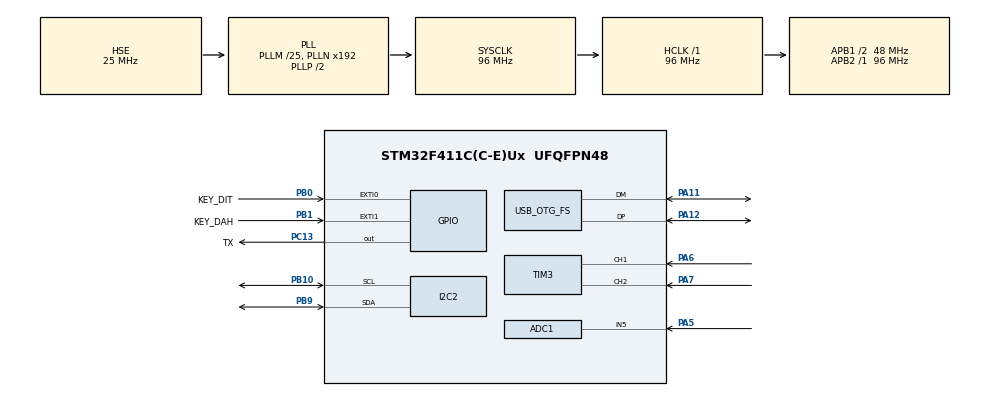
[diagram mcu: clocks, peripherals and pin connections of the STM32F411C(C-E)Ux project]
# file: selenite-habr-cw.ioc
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ADC1.Channel-0\#ChannelRegularConversion=ADC_CHANNEL_5
ADC1.NbrOfConversionFlag=1
ADC1.Rank-0\#ChannelRegularConversion=1
ADC1.SamplingTime-0\#ChannelRegularConversion=ADC_SAMPLETIME_3CYCLES
ADC1.master=1
Mcu.Family=STM32F4
Mcu.Name=STM32F411C(C-E)Ux
Mcu.Package=UFQFPN48
NVIC.ADC_IRQn=true\:0\:0\:false\:false\:true\:true\:true\:true
NVIC.EXTI0_IRQn=true\:0\:0\:false\:false\:true\:true\:true\:true
NVIC.EXTI1_IRQn=true\:0\:0\:false\:false\:true\:true\:true\:true
NVIC.OTG_FS_IRQn=true\:0\:0\:false\:false\:true\:false\:true\:true
NVIC.PriorityGroup=NVIC_PRIORITYGROUP_4
PA11.Mode=Device_Only
PA11.Signal=USB_OTG_FS_DM
PA12.Mode=Device_Only
PA12.Signal=USB_OTG_FS_DP
PA13.Mode=Serial_Wire
PA13.Signal=SYS_JTMS-SWDIO
PA14.Mode=Serial_Wire
PA14.Signal=SYS_JTCK-SWCLK
PA5.Signal=ADCx_IN5
PA6.GPIO_PuPd=GPIO_PULLUP
PA6.Signal=S_TIM3_CH1
PA7.GPIO_PuPd=GPIO_PULLUP
PA7.Signal=S_TIM3_CH2
PB0.GPIO_Label=KEY_DIT
PB0.GPIO_ModeDefaultEXTI=GPIO_MODE_IT_RISING_FALLING
PB0.GPIO_PuPd=GPIO_PULLUP
PB0.Signal=GPXTI0
PB1.GPIO_Label=KEY_DAH
PB1.GPIO_ModeDefaultEXTI=GPIO_MODE_IT_RISING_FALLING
PB1.GPIO_PuPd=GPIO_PULLUP
PB1.Signal=GPXTI1
PB10.Mode=I2C
PB10.Signal=I2C2_SCL
PB9.Mode=I2C
PB9.Signal=I2C2_SDA
PC13-ANTI_TAMP.GPIO_Label=TX
PC13-ANTI_TAMP.PinState=GPIO_PIN_SET
PC13-ANTI_TAMP.Signal=GPIO_Output
PH0\ -\ OSC_IN.Mode=HSE-External-Oscillator
PH0\ -\ OSC_IN.Signal=RCC_OSC_IN
PH1\ -\ OSC_OUT.Mode=HSE-External-Oscillator
PH1\ -\ OSC_OUT.Signal=RCC_OSC_OUT
ProjectManager.HeapSize=0x200
ProjectManager.StackSize=0x400
ProjectManager.TargetToolchain=STM32CubeIDE
RCC.48MHZClocksFreq_Value=48000000
RCC.AHBFreq_Value=96000000
RCC.APB1CLKDivider=RCC_HCLK_DIV2
RCC.APB1Freq_Value=48000000
RCC.APB1TimFreq_Value=96000000
RCC.APB2Freq_Value=96000000
RCC.APB2TimFreq_Value=96000000
RCC.CortexFreq_Value=96000000
RCC.EXTERNAL_CLOCK_VALUE=98304000
RCC.HCLKFreq_Value=96000000
RCC.HSE_VALUE=25000000
RCC.HSI_VALUE=16000000
RCC.LSE_VALUE=32768
RCC.PLLI2SN=128
RCC.PLLI2SR=4
RCC.PLLM=25
RCC.PWREXT_OverDrive=PWREXT_OverDrive_DESACTIVATED
RCC.RCC_MCO1Source=RCC_MCO1SOURCE_HSE
RCC.RCC_RTC_Clock_SourceVirtual=RCC_RTCCLKSOURCE_LSE
RCC.SYSCLKFreq_VALUE=96000000
RCC.SYSCLKSource=RCC_SYSCLKSOURCE_PLLCLK
RCC.VCOOutputFreq_Value=192000000
SH.ADCx_IN5.0=ADC1_IN5,IN5
SH.S_TIM3_CH1.0=TIM3_CH1,Encoder_Interface
SH.S_TIM3_CH2.0=TIM3_CH2,Encoder_Interface
TIM3.EncoderMode=TIM_ENCODERMODE_TI12
USB_DEVICE.APP_RX_DATA_SIZE=64
USB_DEVICE.APP_TX_DATA_SIZE=64
USB_DEVICE.CLASS_NAME_FS=CDC
USB_DEVICE.CONFIGURATION_STRING_CDC_FS=Selenite TRX Config
USB_DEVICE.INTERFACE_STRING_CDC_FS=Selenite TRX Interface
USB_DEVICE.PID_CDC_FS=22347
USB_DEVICE.PRODUCT_STRING_CDC_FS=Selenite TRX
USB_DEVICE.USBD_MAX_NUM_INTERFACES=5
USB_DEVICE.VirtualMode=Cdc
USB_DEVICE.VirtualModeFS=Cdc_FS
USB_OTG_FS.VirtualMode=Device_Only
VP_USB_DEVICE_VS_USB_DEVICE_CDC_FS.Mode=CDC_FS
board=custom

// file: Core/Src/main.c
/* USER CODE BEGIN Header */
/**
  ******************************************************************************
  * @file           : main.c
  * @brief          : Main program body
  ******************************************************************************
  * @attention
  *
  * <h2><center>&copy; Copyright (c) 2021 STMicroelectronics.
  * All rights reserved.</center></h2>
  *
  * This software component is licensed by ST under BSD 3-Clause license,
  * the "License"; You may not use this file except in compliance with the
  * License. You may obtain a copy of the License at:
  *                        opensource.org/licenses/BSD-3-Clause
  *
  ******************************************************************************
  */
/* USER CODE END Header */
#include "main.h"
#include "usb_device.h"

/* USER CODE BEGIN Includes */

#include "ptt_if.h"
#include "user_if.h"
#include "usbd_cdc_if.h"

/* USER CODE END Includes */

ADC_HandleTypeDef hadc1;

I2C_HandleTypeDef hi2c2;

TIM_HandleTypeDef htim3;

/* USER CODE BEGIN PV */

TRX_TypeDef trx;

/* USER CODE END PV */

void SystemClock_Config(void);
static void MX_GPIO_Init(void);
static void MX_ADC1_Init(void);
static void MX_I2C2_Init(void);
static void MX_TIM3_Init(void);

int main(void)
{

  /* MCU Configuration--------------------------------------------------------*/

  /* Reset of all peripherals, Initializes the Flash interface and the Systick. */
  HAL_Init();

  /* Configure the system clock */
  SystemClock_Config();

  /* Initialize all configured peripherals */
  MX_GPIO_Init();
  MX_USB_DEVICE_Init();
  MX_ADC1_Init();
  MX_I2C2_Init();
  MX_TIM3_Init();
  /* USER CODE BEGIN 2 */

  trx.sysclock = 0U;
  trx.systicks = 10U;

  UI_Init ();
  PTT_Init ();

  /* USER CODE END 2 */

  /* Infinite loop */
  /* USER CODE BEGIN WHILE */
  while (1)
  {
    PTT_Handler ();
    UI_Handler ();

    /* USER CODE END WHILE */

  }
}

void SystemClock_Config(void)
{
  RCC_OscInitTypeDef RCC_OscInitStruct = {0};
  RCC_ClkInitTypeDef RCC_ClkInitStruct = {0};

  /** Configure the main internal regulator output voltage
  */
  __HAL_RCC_PWR_CLK_ENABLE();
  __HAL_PWR_VOLTAGESCALING_CONFIG(PWR_REGULATOR_VOLTAGE_SCALE1);

  /** Initializes the RCC Oscillators according to the specified parameters
  * in the RCC_OscInitTypeDef structure.
  */
  RCC_OscInitStruct.OscillatorType = RCC_OSCILLATORTYPE_HSE;
  RCC_OscInitStruct.HSEState = RCC_HSE_ON;
  RCC_OscInitStruct.PLL.PLLState = RCC_PLL_ON;
  RCC_OscInitStruct.PLL.PLLSource = RCC_PLLSOURCE_HSE;
  RCC_OscInitStruct.PLL.PLLM = 25;
  RCC_OscInitStruct.PLL.PLLN = 192;
  RCC_OscInitStruct.PLL.PLLP = RCC_PLLP_DIV2;
  RCC_OscInitStruct.PLL.PLLQ = 4;
  if (HAL_RCC_OscConfig(&RCC_OscInitStruct) != HAL_OK)
  {
    Error_Handler();
  }

  /** Initializes the CPU, AHB and APB buses clocks
  */
  RCC_ClkInitStruct.ClockType = RCC_CLOCKTYPE_HCLK|RCC_CLOCKTYPE_SYSCLK
                              |RCC_CLOCKTYPE_PCLK1|RCC_CLOCKTYPE_PCLK2;
  RCC_ClkInitStruct.SYSCLKSource = RCC_SYSCLKSOURCE_PLLCLK;
  RCC_ClkInitStruct.AHBCLKDivider = RCC_SYSCLK_DIV1;
  RCC_ClkInitStruct.APB1CLKDivider = RCC_HCLK_DIV2;
  RCC_ClkInitStruct.APB2CLKDivider = RCC_HCLK_DIV1;

  if (HAL_RCC_ClockConfig(&RCC_ClkInitStruct, FLASH_LATENCY_3) != HAL_OK)
  {
    Error_Handler();
  }
}

static void MX_ADC1_Init(void)
{

  ADC_ChannelConfTypeDef sConfig = {0};

  /** Configure the global features of the ADC (Clock, Resolution, Data Alignment and number of conversion)
  */
  hadc1.Instance = ADC1;
  hadc1.Init.ClockPrescaler = ADC_CLOCK_SYNC_PCLK_DIV4;
  hadc1.Init.Resolution = ADC_RESOLUTION_12B;
  hadc1.Init.ScanConvMode = DISABLE;
  hadc1.Init.ContinuousConvMode = DISABLE;
  hadc1.Init.DiscontinuousConvMode = DISABLE;
  hadc1.Init.ExternalTrigConvEdge = ADC_EXTERNALTRIGCONVEDGE_NONE;
  hadc1.Init.ExternalTrigConv = ADC_SOFTWARE_START;
  hadc1.Init.DataAlign = ADC_DATAALIGN_RIGHT;
  hadc1.Init.NbrOfConversion = 1;
  hadc1.Init.DMAContinuousRequests = DISABLE;
  hadc1.Init.EOCSelection = ADC_EOC_SINGLE_CONV;
  if (HAL_ADC_Init(&hadc1) != HAL_OK)
  {
    Error_Handler();
  }

  /** Configure for the selected ADC regular channel its corresponding rank in the sequencer and its sample time.
  */
  sConfig.Channel = ADC_CHANNEL_5;
  sConfig.Rank = 1;
  sConfig.SamplingTime = ADC_SAMPLETIME_3CYCLES;
  if (HAL_ADC_ConfigChannel(&hadc1, &sConfig) != HAL_OK)
  {
    Error_Handler();
  }

}

static void MX_I2C2_Init(void)
{

  hi2c2.Instance = I2C2;
  hi2c2.Init.ClockSpeed = 100000;
  hi2c2.Init.DutyCycle = I2C_DUTYCYCLE_2;
  hi2c2.Init.OwnAddress1 = 0;
  hi2c2.Init.AddressingMode = I2C_ADDRESSINGMODE_7BIT;
  hi2c2.Init.DualAddressMode = I2C_DUALADDRESS_DISABLE;
  hi2c2.Init.OwnAddress2 = 0;
  hi2c2.Init.GeneralCallMode = I2C_GENERALCALL_DISABLE;
  hi2c2.Init.NoStretchMode = I2C_NOSTRETCH_DISABLE;
  if (HAL_I2C_Init(&hi2c2) != HAL_OK)
  {
    Error_Handler();
  }

}

static void MX_TIM3_Init(void)
{

  TIM_Encoder_InitTypeDef sConfig = {0};
  TIM_MasterConfigTypeDef sMasterConfig = {0};

  htim3.Instance = TIM3;
  htim3.Init.Prescaler = 0;
  htim3.Init.CounterMode = TIM_COUNTERMODE_UP;
  htim3.Init.Period = 65535;
  htim3.Init.ClockDivision = TIM_CLOCKDIVISION_DIV1;
  htim3.Init.AutoReloadPreload = TIM_AUTORELOAD_PRELOAD_DISABLE;
  sConfig.EncoderMode = TIM_ENCODERMODE_TI12;
  sConfig.IC1Polarity = TIM_ICPOLARITY_RISING;
  sConfig.IC1Selection = TIM_ICSELECTION_DIRECTTI;
  sConfig.IC1Prescaler = TIM_ICPSC_DIV1;
  sConfig.IC1Filter = 0;
  sConfig.IC2Polarity = TIM_ICPOLARITY_RISING;
  sConfig.IC2Selection = TIM_ICSELECTION_DIRECTTI;
  sConfig.IC2Prescaler = TIM_ICPSC_DIV1;
  sConfig.IC2Filter = 0;
  if (HAL_TIM_Encoder_Init(&htim3, &sConfig) != HAL_OK)
  {
    Error_Handler();
  }
  sMasterConfig.MasterOutputTrigger = TIM_TRGO_RESET;
  sMasterConfig.MasterSlaveMode = TIM_MASTERSLAVEMODE_DISABLE;
  if (HAL_TIMEx_MasterConfigSynchronization(&htim3, &sMasterConfig) != HAL_OK)
  {
    Error_Handler();
  }

}

static void MX_GPIO_Init(void)
{
  GPIO_InitTypeDef GPIO_InitStruct = {0};

  /* GPIO Ports Clock Enable */
  __HAL_RCC_GPIOC_CLK_ENABLE();
  __HAL_RCC_GPIOH_CLK_ENABLE();
  __HAL_RCC_GPIOA_CLK_ENABLE();
  __HAL_RCC_GPIOB_CLK_ENABLE();

  /*Configure GPIO pin Output Level */
  HAL_GPIO_WritePin(TX_GPIO_Port, TX_Pin, GPIO_PIN_SET);

  /*Configure GPIO pin : TX_Pin */
  GPIO_InitStruct.Pin = TX_Pin;
  GPIO_InitStruct.Mode = GPIO_MODE_OUTPUT_PP;
  GPIO_InitStruct.Pull = GPIO_NOPULL;
  GPIO_InitStruct.Speed = GPIO_SPEED_FREQ_LOW;
  HAL_GPIO_Init(TX_GPIO_Port, &GPIO_InitStruct);

  /*Configure GPIO pins : KEY_DIT_Pin KEY_DAH_Pin */
  GPIO_InitStruct.Pin = KEY_DIT_Pin|KEY_DAH_Pin;
  GPIO_InitStruct.Mode = GPIO_MODE_IT_RISING_FALLING;
  GPIO_InitStruct.Pull = GPIO_PULLUP;
  HAL_GPIO_Init(GPIOB, &GPIO_InitStruct);

  /* EXTI interrupt init*/
  HAL_NVIC_SetPriority(EXTI0_IRQn, 0, 0);
  HAL_NVIC_EnableIRQ(EXTI0_IRQn);

  HAL_NVIC_SetPriority(EXTI1_IRQn, 0, 0);
  HAL_NVIC_EnableIRQ(EXTI1_IRQn);

}

void Error_Handler(void)
{
}
